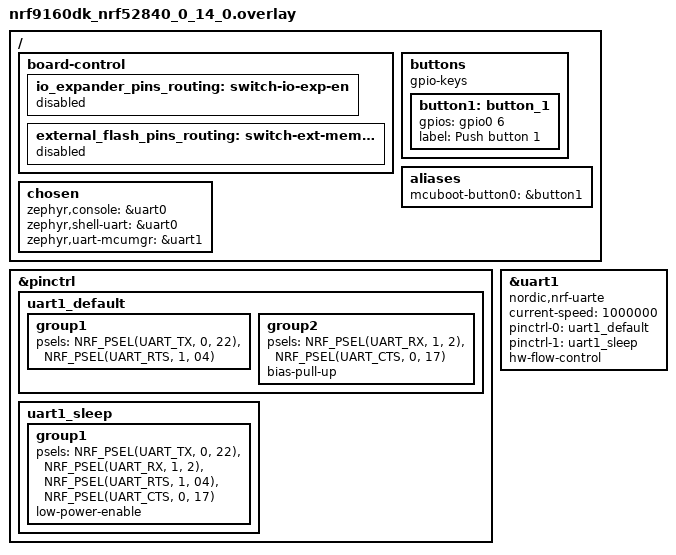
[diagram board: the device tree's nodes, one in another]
/*
 * Copyright (c) 2023 Nordic Semiconductor ASA
 *
 * SPDX-License-Identifier: LicenseRef-Nordic-5-Clause
 */
#include <nrf9160dk_nrf52840_reset_on_if9.dtsi>
#include <nrf9160dk_uart1_on_if0_3.dtsi>

/ {
	board-control {

		io_expander_pins_routing: switch-io-exp-en {
			status = "disabled";
		};

		external_flash_pins_routing: switch-ext-mem-ctrl {
			status = "disabled";
		};
	};
};

/ {
	buttons {
		compatible = "gpio-keys";
		button1: button_1 {
			gpios = <&gpio0 6 (GPIO_PULL_DOWN | GPIO_ACTIVE_HIGH)>;
			label = "Push button 1";
		};
	};

	aliases {
		mcuboot-button0 = &button1;
	};
};

&pinctrl {
	uart1_default: uart1_default {
		group1 {
			psels = <NRF_PSEL(UART_TX, 0, 22)>,
				<NRF_PSEL(UART_RTS, 1, 04)>;
		};
		group2 {
			psels = <NRF_PSEL(UART_RX, 1, 2)>,
				<NRF_PSEL(UART_CTS, 0, 17)>;
			bias-pull-up;
		};
	};

	uart1_sleep: uart1_sleep {
		group1 {
			psels =<NRF_PSEL(UART_TX, 0, 22)>,
				<NRF_PSEL(UART_RX, 1, 2)>,
				<NRF_PSEL(UART_RTS, 1, 04)>,
				<NRF_PSEL(UART_CTS, 0, 17)>;
			low-power-enable;
		};
	};

};

&uart1 {
	compatible = "nordic,nrf-uarte";
	current-speed = <1000000>;
	pinctrl-0 = <&uart1_default>;
	pinctrl-1 = <&uart1_sleep>;
	hw-flow-control;
};

/ {
        chosen {
                zephyr,console = &uart0;
                zephyr,shell-uart = &uart0;
                zephyr,uart-mcumgr = &uart1;
        };
};
